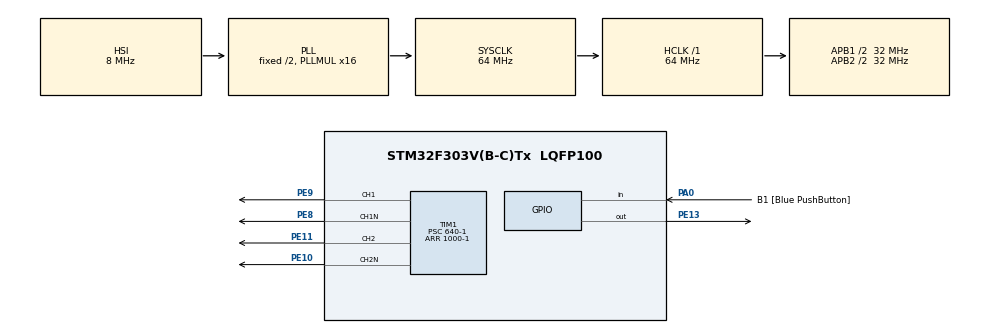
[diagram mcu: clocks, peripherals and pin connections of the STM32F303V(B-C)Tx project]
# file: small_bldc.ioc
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Mcu.Family=STM32F3
Mcu.Name=STM32F303V(B-C)Tx
Mcu.Package=LQFP100
NVIC.PriorityGroup=NVIC_PRIORITYGROUP_0
NVIC.TIM1_UP_TIM16_IRQn=true\:0\:0\:false\:false\:true\:true\:true
PA0.GPIO_Label=B1 [Blue PushButton]
PA0.Signal=GPIO_Input
PE10.GPIO_Speed=GPIO_SPEED_FREQ_HIGH
PE10.Mode=PWM Generation2 CH2 CH2N
PE10.Signal=TIM1_CH2N
PE11.GPIO_Speed=GPIO_SPEED_FREQ_HIGH
PE11.Signal=S_TIM1_CH2
PE13.Signal=GPIO_Output
PE8.GPIO_Speed=GPIO_SPEED_FREQ_HIGH
PE8.Mode=PWM Generation1 CH1 CH1N
PE8.Signal=TIM1_CH1N
PE9.GPIO_Speed=GPIO_SPEED_FREQ_HIGH
PE9.Signal=S_TIM1_CH1
PF0-OSC_IN.GPIO_Label=OSC_IN
PF0-OSC_IN.Mode=HSE-External-Oscillator
PF0-OSC_IN.Signal=RCC_OSC_IN
PF1-OSC_OUT.Mode=HSE-External-Oscillator
PF1-OSC_OUT.Signal=RCC_OSC_OUT
ProjectManager.HeapSize=0x200
ProjectManager.StackSize=0x400
ProjectManager.TargetToolchain=SW4STM32
RCC.AHBFreq_Value=64000000
RCC.APB1CLKDivider=RCC_HCLK_DIV2
RCC.APB1Freq_Value=32000000
RCC.APB1TimFreq_Value=64000000
RCC.APB2CLKDivider=RCC_HCLK_DIV2
RCC.APB2Freq_Value=32000000
RCC.APB2TimFreq_Value=64000000
RCC.CortexFreq_Value=64000000
RCC.HCLKFreq_Value=64000000
RCC.HSE_VALUE=8000000
RCC.HSI_VALUE=8000000
RCC.LSE_VALUE=32768
RCC.PLLMUL=RCC_PLL_MUL16
RCC.SYSCLKFreq_VALUE=64000000
RCC.SYSCLKSourceVirtual=RCC_SYSCLKSOURCE_PLLCLK
RCC.USBFreq_Value=64000000
SH.S_TIM1_CH1.0=TIM1_CH1,PWM Generation1 CH1 CH1N
SH.S_TIM1_CH2.0=TIM1_CH2,PWM Generation2 CH2 CH2N
TIM1.Channel-PWM\ Generation1\ CH1\ CH1N=TIM_CHANNEL_1
TIM1.Channel-PWM\ Generation2\ CH2\ CH2N=TIM_CHANNEL_2
TIM1.OCFastMode_PWM-PWM\ Generation1\ CH1\ CH1N=TIM_OCFAST_ENABLE
TIM1.OCFastMode_PWM-PWM\ Generation2\ CH2\ CH2N=TIM_OCFAST_ENABLE
TIM1.Period=1000-1
TIM1.Prescaler=640-1
VP_TIM1_VS_ClockSourceINT.Mode=Internal
board=STM32F3DISCOVERY

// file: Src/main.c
/* USER CODE BEGIN Header */
/**
  ******************************************************************************
  * @file           : main.c
  * @brief          : Main program body
  ******************************************************************************
  * @attention
  *
  * <h2><center>&copy; Copyright (c) 2019 STMicroelectronics.
  * All rights reserved.</center></h2>
  *
  * This software component is licensed by ST under BSD 3-Clause license,
  * the "License"; You may not use this file except in compliance with the
  * License. You may obtain a copy of the License at:
  *                        opensource.org/licenses/BSD-3-Clause
  *
  ******************************************************************************
  */
/* USER CODE END Header */

#include "main.h"
#include "tim.h"
#include "gpio.h"

/* USER CODE BEGIN Includes */
#include "tim.h"
/* USER CODE END Includes */

void SystemClock_Config(void);

/* USER CODE BEGIN 0 */
//volatile uint8_t statuss = 0;
//void HAL_TIM_PeriodElapsedCallback(TIM_HandleTypeDef *htim)
//{
//	if(htim->Instance == TIM1) //check if the interrupt comes from TIM1
//	{
////		HAL_GPIO_TogglePin(GPIOE, GPIO_PIN_13);
//		if (statuss == 0) {
//			statuss = 0;
//			HAL_TIMEx_PWMN_Stop(&htim1, TIM_CHANNEL_1);
//			HAL_TIMEx_PWMN_Start(&htim1, TIM_CHANNEL_2);
//		} else {
//			statuss = 1;
//			HAL_TIMEx_PWMN_Stop(&htim1, TIM_CHANNEL_2);
//			HAL_TIMEx_PWMN_Start(&htim1, TIM_CHANNEL_1);
//		}
//	}
//}
/* USER CODE END 0 */

int main(void)
{

  /* MCU Configuration--------------------------------------------------------*/

  /* Reset of all peripherals, Initializes the Flash interface and the Systick. */
  HAL_Init();

  /* Configure the system clock */
  SystemClock_Config();

  /* Initialize all configured peripherals */
  MX_GPIO_Init();
  MX_TIM1_Init();
  /* USER CODE BEGIN 2 */
  HAL_TIM_Base_Start_IT(&htim1);

  TIM1->CCR2 = 500;
  TIM1->CCR1 = 500;
  // stm32f3xx_it.c the main code
  /* USER CODE END 2 */

  /* Infinite loop */
  /* USER CODE BEGIN WHILE */
  while (1)
  {
//	  HAL_GPIO_TogglePin(GPIOE, GPIO_PIN_13);
//	  HAL_Delay(500);
    /* USER CODE END WHILE */

  }
}

void SystemClock_Config(void)
{
  RCC_OscInitTypeDef RCC_OscInitStruct = {0};
  RCC_ClkInitTypeDef RCC_ClkInitStruct = {0};
  RCC_PeriphCLKInitTypeDef PeriphClkInit = {0};

  /** Initializes the CPU, AHB and APB busses clocks
  */
  RCC_OscInitStruct.OscillatorType = RCC_OSCILLATORTYPE_HSI;
  RCC_OscInitStruct.HSIState = RCC_HSI_ON;
  RCC_OscInitStruct.HSICalibrationValue = RCC_HSICALIBRATION_DEFAULT;
  RCC_OscInitStruct.PLL.PLLState = RCC_PLL_ON;
  RCC_OscInitStruct.PLL.PLLSource = RCC_PLLSOURCE_HSI;
  RCC_OscInitStruct.PLL.PLLMUL = RCC_PLL_MUL16;
  if (HAL_RCC_OscConfig(&RCC_OscInitStruct) != HAL_OK)
  {
    Error_Handler();
  }
  /** Initializes the CPU, AHB and APB busses clocks
  */
  RCC_ClkInitStruct.ClockType = RCC_CLOCKTYPE_HCLK|RCC_CLOCKTYPE_SYSCLK
                              |RCC_CLOCKTYPE_PCLK1|RCC_CLOCKTYPE_PCLK2;
  RCC_ClkInitStruct.SYSCLKSource = RCC_SYSCLKSOURCE_PLLCLK;
  RCC_ClkInitStruct.AHBCLKDivider = RCC_SYSCLK_DIV1;
  RCC_ClkInitStruct.APB1CLKDivider = RCC_HCLK_DIV2;
  RCC_ClkInitStruct.APB2CLKDivider = RCC_HCLK_DIV2;

  if (HAL_RCC_ClockConfig(&RCC_ClkInitStruct, FLASH_LATENCY_2) != HAL_OK)
  {
    Error_Handler();
  }
  PeriphClkInit.PeriphClockSelection = RCC_PERIPHCLK_TIM1;
  PeriphClkInit.Tim1ClockSelection = RCC_TIM1CLK_HCLK;
  if (HAL_RCCEx_PeriphCLKConfig(&PeriphClkInit) != HAL_OK)
  {
    Error_Handler();
  }
}

void Error_Handler(void)
{
}

/************************ (C) COPYRIGHT STMicroelectronics *****END OF FILE****/
